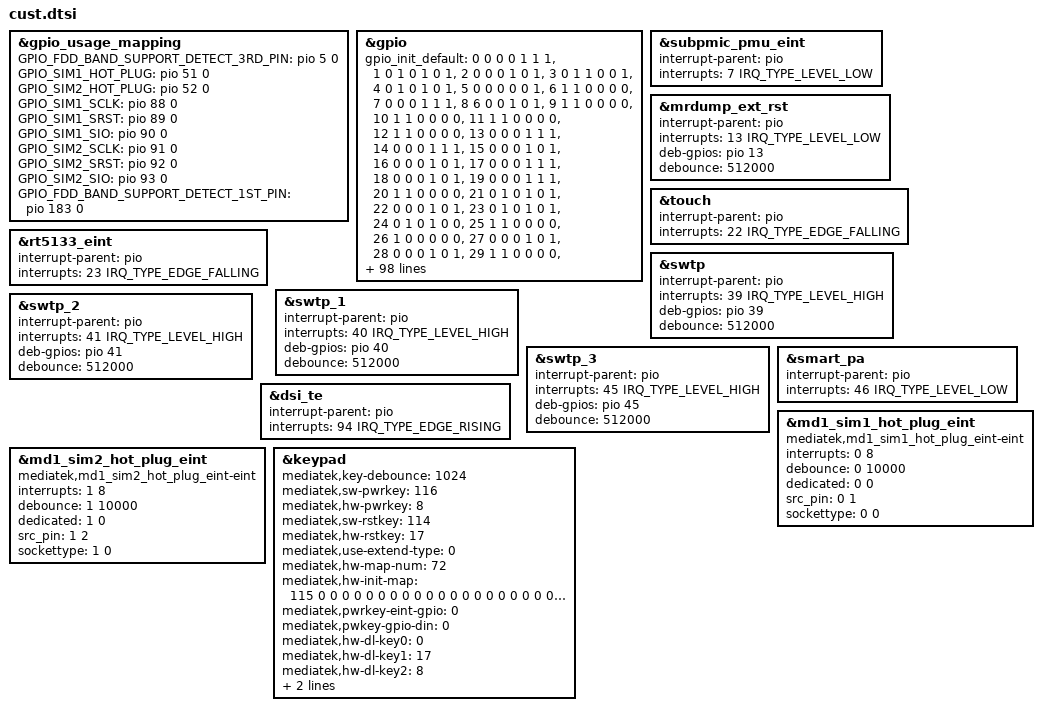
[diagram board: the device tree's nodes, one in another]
/*
 * Generated by MTK SP DrvGen Version: 3.5.160809 for MT6855.
 * 2025-09-28 15:51:00
 * Do Not Modify The File.
 * Copyright Mediatek Inc. (c) 2016.
*/

/*************************
 * ADC DTSI File
*************************/



/*************************
 * CLK_BUF DTSI File
*************************/



/*************************
 * I2C DTSI File
*************************/



/*************************
 * GPIO DTSI File
*************************/

&gpio_usage_mapping {
	GPIO_FDD_BAND_SUPPORT_DETECT_3RD_PIN = <&pio 5 0>;
	GPIO_SIM1_HOT_PLUG = <&pio 51 0>;
	GPIO_SIM2_HOT_PLUG = <&pio 52 0>;
	GPIO_SIM1_SCLK = <&pio 88 0>;
	GPIO_SIM1_SRST = <&pio 89 0>;
	GPIO_SIM1_SIO = <&pio 90 0>;
	GPIO_SIM2_SCLK = <&pio 91 0>;
	GPIO_SIM2_SRST = <&pio 92 0>;
	GPIO_SIM2_SIO = <&pio 93 0>;
	GPIO_FDD_BAND_SUPPORT_DETECT_1ST_PIN = <&pio 183 0>;
};

&gpio{
	gpio_init_default = <0 0 0 0 1 1 1>,
		<1 0 1 0 1 0 1>,
		<2 0 0 0 1 0 1>,
		<3 0 1 1 0 0 1>,
		<4 0 1 0 1 0 1>,
		<5 0 0 0 0 0 1>,
		<6 1 1 0 0 0 0>,
		<7 0 0 0 1 1 1>,
		<8 6 0 0 1 0 1>,
		<9 1 1 0 0 0 0>,
		<10 1 1 0 0 0 0>,
		<11 1 1 0 0 0 0>,
		<12 1 1 0 0 0 0>,
		<13 0 0 0 1 1 1>,
		<14 0 0 0 1 1 1>,
		<15 0 0 0 1 0 1>,
		<16 0 0 0 1 0 1>,
		<17 0 0 0 1 1 1>,
		<18 0 0 0 1 0 1>,
		<19 0 0 0 1 1 1>,
		<20 1 1 0 0 0 0>,
		<21 0 1 0 1 0 1>,
		<22 0 0 0 1 0 1>,
		<23 0 1 0 1 0 1>,
		<24 0 1 0 1 0 0>,
		<25 1 1 0 0 0 0>,
		<26 1 0 0 0 0 0>,
		<27 0 0 0 1 0 1>,
		<28 0 0 0 1 0 1>,
		<29 1 1 0 0 0 0>,
		<30 0 1 0 1 0 1>,
		<31 1 1 0 0 0 0>,
		<32 1 1 0 0 0 0>,
		<33 0 0 0 1 0 1>,
		<34 0 0 0 1 0 1>,
		<35 3 0 0 1 1 1>,
		<36 3 0 0 0 0 1>,
		<37 3 0 0 0 0 1>,
		<38 0 1 0 1 0 1>,
		<39 0 0 0 1 1 1>,
		<40 0 0 0 1 1 1>,
		<41 0 0 0 1 1 1>,
		<42 1 0 0 0 0 1>,
		<43 1 1 0 0 0 1>,
		<44 1 1 0 0 0 1>,
		<45 0 0 0 1 1 1>,
		<46 0 0 0 1 1 1>,
		<47 1 0 0 0 0 1>,
		<48 1 0 0 0 0 1>,
		<49 1 0 0 0 0 1>,
		<50 3 0 0 1 0 1>,
		<51 1 0 0 1 1 1>,
		<52 1 0 0 1 1 1>,
		<53 1 0 0 0 0 1>,
		<54 1 0 0 1 1 1>,
		<55 1 0 0 0 0 1>,
		<56 1 0 0 1 1 1>,
		<57 1 0 0 1 0 1>,
		<58 0 1 0 1 0 1>,
		<59 1 0 0 1 1 1>,
		<60 7 0 0 1 0 1>,
		<61 7 0 0 1 0 1>,
		<62 7 0 0 1 0 1>,
		<63 7 0 0 0 0 1>,
		<64 7 0 0 1 0 1>,
		<65 2 0 0 0 0 1>,
		<66 2 0 0 1 1 1>,
		<67 2 0 0 0 0 1>,
		<68 2 0 0 1 0 1>,
		<69 1 0 0 0 0 1>,
		<70 1 0 0 0 0 1>,
		<71 1 0 0 0 0 1>,
		<72 1 0 0 1 0 1>,
		<73 2 1 0 0 0 1>,
		<74 2 1 1 0 0 1>,
		<75 2 1 0 0 0 1>,
		<76 2 0 0 1 0 1>,
		<77 1 0 0 0 0 1>,
		<78 1 0 0 0 0 1>,
		<79 1 0 0 0 0 1>,
		<80 1 0 0 1 0 1>,
		<82 1 0 0 0 0 1>,
		<83 1 0 0 1 1 1>,
		<84 1 0 0 1 1 1>,
		<85 1 0 0 1 1 1>,
		<86 1 0 0 1 1 1>,
		<87 1 0 0 1 1 1>,
		<88 1 0 0 0 0 1>,
		<89 1 0 0 0 0 1>,
		<90 1 0 0 1 1 1>,
		<91 1 0 0 0 0 1>,
		<92 1 0 0 0 0 1>,
		<93 1 0 0 1 1 1>,
		<94 1 0 0 1 0 1>,
		<95 1 0 0 0 0 1>,
		<96 1 0 0 0 0 1>,
		<97 1 1 0 0 0 0>,
		<98 1 0 0 1 0 1>,
		<99 1 1 0 0 0 0>,
		<100 1 1 0 0 0 0>,
		<101 0 0 0 0 0 1>,
		<102 0 0 0 0 0 1>,
		<103 1 0 0 1 0 1>,
		<104 1 0 0 1 0 1>,
		<105 1 0 0 0 0 1>,
		<106 1 0 0 0 0 1>,
		<107 1 0 0 0 0 1>,
		<108 1 0 0 0 0 1>,
		<109 1 0 0 0 0 1>,
		<110 1 0 0 0 0 1>,
		<111 1 0 0 0 0 1>,
		<112 1 0 0 0 0 1>,
		<113 1 0 0 0 0 1>,
		<114 1 0 0 0 0 1>,
		<115 1 0 0 0 0 1>,
		<116 1 0 0 0 0 1>,
		<117 1 0 0 0 0 1>,
		<118 1 0 0 0 0 1>,
		<119 1 0 0 0 0 1>,
		<120 1 0 0 0 0 1>,
		<121 1 0 0 0 0 1>,
		<122 1 0 0 0 0 1>,
		<123 1 0 0 0 0 1>,
		<124 1 0 0 0 0 1>,
		<125 1 0 0 0 0 1>,
		<126 1 0 0 0 0 1>,
		<127 1 0 0 0 0 0>,
		<128 1 0 0 1 0 0>,
		<129 1 0 0 0 0 0>,
		<130 1 0 0 1 0 0>,
		<131 1 0 0 0 0 0>,
		<132 1 0 0 1 0 0>,
		<133 3 0 0 1 0 1>,
		<134 3 0 0 1 0 1>,
		<135 1 0 0 1 0 1>,
		<136 1 0 0 1 0 1>,
		<137 1 0 0 1 1 1>,
		<138 1 0 0 1 1 1>,
		<139 2 0 0 1 1 1>,
		<140 2 0 0 1 1 1>,
		<141 1 0 0 1 1 1>,
		<142 1 0 0 1 1 1>,
		<143 1 0 0 1 1 1>,
		<144 1 0 0 1 1 1>,
		<145 1 0 0 1 1 1>,
		<146 1 0 0 1 1 1>,
		<147 1 0 0 1 1 1>,
		<148 1 0 0 1 1 1>,
		<149 1 0 0 1 1 1>,
		<150 1 0 0 1 1 1>,
		<151 1 0 0 1 1 1>,
		<152 1 0 0 1 1 1>,
		<153 1 0 0 1 1 1>,
		<154 1 0 0 1 1 1>,
		<155 1 0 0 1 1 1>,
		<156 1 0 0 1 1 1>,
		<157 0 1 0 1 0 1>,
		<158 0 1 0 1 0 1>,
		<159 0 1 0 1 0 1>,
		<160 3 0 0 1 0 1>,
		<161 0 1 0 1 0 1>,
		<162 0 1 0 1 0 1>,
		<163 1 0 0 0 0 1>,
		<164 1 0 0 0 0 1>,
		<165 1 0 0 0 0 1>,
		<166 1 0 0 0 0 1>,
		<167 1 0 0 0 0 1>,
		<168 1 0 0 0 0 1>,
		<169 1 0 0 0 0 1>,
		<170 1 0 0 1 0 1>,
		<171 1 0 0 0 0 1>,
		<172 1 0 0 0 0 1>,
		<173 1 0 0 0 0 1>,
		<174 1 0 0 0 0 1>,
		<175 1 0 0 0 0 1>,
		<176 1 0 0 0 0 1>,
		<177 1 0 0 0 0 1>,
		<178 1 0 0 0 0 1>,
		<179 1 0 0 1 0 1>,
		<180 1 0 0 1 0 1>,
		<181 1 0 0 1 0 1>,
		<182 0 1 0 1 0 1>,
		<183 0 0 0 0 0 1>,
		<184 0 0 0 1 0 1>,
		<185 0 0 0 1 0 1>,
		<186 0 0 0 1 0 1>,
		<187 0 0 0 1 0 1>,
		<188 0 0 0 1 0 1>,
		<189 0 0 0 1 0 1>,
		<190 0 0 0 1 0 1>,
		<191 0 0 0 1 0 1>,
		<192 0 0 0 1 0 1>,
		<193 1 0 0 0 0 1>,
		<194 0 1 0 1 0 1>,
		<195 0 1 0 1 0 1>,
		<196 1 0 0 1 1 1>,
		<197 1 0 0 0 0 1>,
		<198 1 0 0 1 1 1>,
		<199 0 1 0 1 0 1>,
		<200 1 0 0 1 1 1>,
		<201 1 0 0 1 1 1>,
		<202 1 0 0 1 1 1>,
		<203 0 1 0 1 0 1>,
		<204 1 0 0 1 1 1>,
		<205 0 1 0 1 0 1>,
		<206 0 0 0 1 0 0>,
		<207 0 0 0 1 0 0>,
		<208 0 0 0 1 0 0>,
		<209 0 0 0 1 0 0>,
		<210 0 0 0 1 0 0>,
		<211 0 0 0 1 0 0>,
		<212 0 0 0 1 0 0>,
		<213 0 0 0 1 0 0>,
		<214 0 0 0 1 0 0>,
		<215 0 0 0 1 0 0>,
		<216 0 0 0 1 0 0>,
		<217 0 0 0 1 0 0>,
		<218 0 0 0 1 0 0>,
		<219 0 0 0 1 0 0>,
		<220 0 0 0 1 0 0>,
		<221 0 0 0 1 0 0>,
		<222 0 0 0 1 0 0>,
		<223 0 0 0 1 0 0>,
		<224 0 0 0 1 0 0>,
		<225 0 0 0 1 0 0>;
};


/*************************
 * EINT DTSI File
*************************/

#include <dt-bindings/interrupt-controller/irq.h>
#include <dt-bindings/interrupt-controller/arm-gic.h>

&subpmic_pmu_eint {
	interrupt-parent = <&pio>;
	interrupts = <7 IRQ_TYPE_LEVEL_LOW>;
	status = "okay";
};

&mrdump_ext_rst {
	interrupt-parent = <&pio>;
	interrupts = <13 IRQ_TYPE_LEVEL_LOW>;
	deb-gpios = <&pio 13 0>;
	debounce = <512000>;
	status = "okay";
};

&touch {
	interrupt-parent = <&pio>;
	interrupts = <22 IRQ_TYPE_EDGE_FALLING>;
	status = "okay";
};

&rt5133_eint {
	interrupt-parent = <&pio>;
	interrupts = <23 IRQ_TYPE_EDGE_FALLING>;
	status = "okay";
};

&swtp {
	interrupt-parent = <&pio>;
	interrupts = <39 IRQ_TYPE_LEVEL_HIGH>;
	deb-gpios = <&pio 39 0>;
	debounce = <512000>;
	status = "okay";
};

&swtp_1 {
	interrupt-parent = <&pio>;
	interrupts = <40 IRQ_TYPE_LEVEL_HIGH>;
	deb-gpios = <&pio 40 0>;
	debounce = <512000>;
	status = "okay";
};

&swtp_2 {
	interrupt-parent = <&pio>;
	interrupts = <41 IRQ_TYPE_LEVEL_HIGH>;
	deb-gpios = <&pio 41 0>;
	debounce = <512000>;
	status = "okay";
};

&swtp_3 {
	interrupt-parent = <&pio>;
	interrupts = <45 IRQ_TYPE_LEVEL_HIGH>;
	deb-gpios = <&pio 45 0>;
	debounce = <512000>;
	status = "okay";
};

&smart_pa {
	interrupt-parent = <&pio>;
	interrupts = <46 IRQ_TYPE_LEVEL_LOW>;
	status = "okay";
};

&dsi_te {
	interrupt-parent = <&pio>;
	interrupts = <94 IRQ_TYPE_EDGE_RISING>;
	status = "okay";
};



/*************************
 * MD1_EINT DTSI File
*************************/

&md1_sim1_hot_plug_eint {
	compatible = "mediatek,md1_sim1_hot_plug_eint-eint";
	interrupts = <0 8>;
	debounce = <0 10000>;
	dedicated = <0 0>;
	src_pin = <0 1>;
	sockettype = <0 0>;
	status = "okay";
};

&md1_sim2_hot_plug_eint {
	compatible = "mediatek,md1_sim2_hot_plug_eint-eint";
	interrupts = <1 8>;
	debounce = <1 10000>;
	dedicated = <1 0>;
	src_pin = <1 2>;
	sockettype = <1 0>;
	status = "okay";
};



/*************************
 * PMIC DTSI File
*************************/



/*************************
 * POWER DTSI File
*************************/



/*************************
 * KPD DTSI File
*************************/

&keypad {
	mediatek,key-debounce = <1024>;
	mediatek,sw-pwrkey = <116>;
	mediatek,hw-pwrkey = <8>;
	mediatek,sw-rstkey  = <114>;
	mediatek,hw-rstkey = <17>;
	mediatek,use-extend-type = <0>;
	/*HW Keycode [0~71] -> Linux Keycode*/
	mediatek,hw-map-num = <72>;
	mediatek,hw-init-map = <115 0 0 0 0 0 0 0 0 0 0 0 0 0 0 0 0 0 0 0 0 0 0 0 0 0 0 0 0 0 0 0 0 0 0 0 0 0 0 0 0 0 0 0 0 0 0 0 0 0 0 0 0 0 0 0 0 0 0 0 0 0 0 0 0 0 0 0 0 0 0 0 >;
	mediatek,pwrkey-eint-gpio = <0>;
	mediatek,pwkey-gpio-din  = <0>;
	mediatek,hw-dl-key0 = <0>;
	mediatek,hw-dl-key1 = <17>;
	mediatek,hw-dl-key2 = <8>;
	mediatek,hw-recovery-key = <0>;
	mediatek,hw-factory-key = <17>;
	status = "okay";
};


